# NAVSS0_TIMERMGR_0_TIMERMGR0_CFG_CONFIG register map
Vendor: Texas Instruments
Peripheral module from a debugger description file (folder J721S2).
Registers are 32-bit, read-only, reset 0x0 unless marked. A register's access mark holds for its fields unless they carry their own. Offsets are as the file gives them; lines under a group give offsets from that group; [hi:lo] are bit positions; {n}, {i} and the like mark numbered series; 'fields as' and 'values as' point back to an identical list; <NAME> marks a mode.

## NAVSS0_TIMERMGR_0_TIMERMGR0_CFG_CONFIG
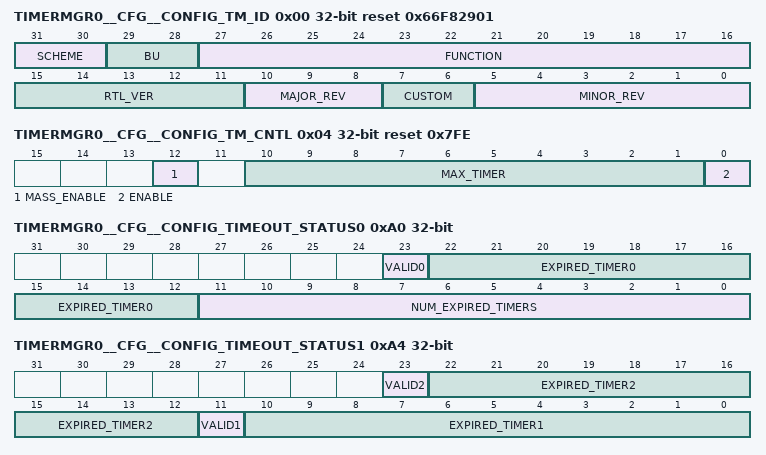
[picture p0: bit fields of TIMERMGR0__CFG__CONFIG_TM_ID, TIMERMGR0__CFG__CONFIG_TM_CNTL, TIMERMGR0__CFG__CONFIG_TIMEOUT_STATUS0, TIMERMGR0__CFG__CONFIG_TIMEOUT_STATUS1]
0x00 TIMERMGR0__CFG__CONFIG_TM_ID reset 0x66F82901 — This is the standard TI peripheral ID register that exists at address 0 in the peripheral space
  [31:30] SCHEME — PID scheme
  [29:28] BU — PID bu identifier
  [27:16] FUNCTION — PID function identifier
  [15:11] RTL_VER — PID RTL version number
  [10:8] MAJOR_REV — PID Major revision number
  [7:6] CUSTOM — PID custom
  [5:0] MINOR_REV — PID Minor revision number
0x04 TIMERMGR0__CFG__CONFIG_TM_CNTL access per field reset 0x7FE — This register controls the overall behavior of the timer manager module
  [12] MASS_ENABLE wo — Always reads zero. When a 1 is written to this bit, all timers from 0 to the TM_CNTL.max_timer will be enabled. Useful for initial programming, to not need to loop over every TIMER_CONTROL register to enable every timer if many or all are being used. This should only be used during initialization, or when TM_CNTL.enable is set to 0, as this does not set the timers, only enable them
  [10:1] MAX_TIMER rw — The maximum timer that will be checked - e.g. if only using 512 timers, set this to 511. All timers above this number will be ignored. Should be set once during initialization
  [0] ENABLE rw — Enables the timer manager. When this bit is zero, the timers will all be halted and will not count
0x08 TIMERMGR0__CFG__CONFIG_TIMER_COUNTER — This register contains the current counter value
  [31:0] COUNT — The current timer_counter value, in the timebase being used by all timers in this module
0xA0 TIMERMGR0__CFG__CONFIG_TIMEOUT_STATUS0 — This register should be read whenever the timer interrupt fires. It indicates the total number of timers that have expired and the ID of the first timer to expire. If NUM_EXPIRED_TIMERS is 1, this is the only MMR that needs to be read. Depending on the value of NUM_EXPIRED_TIMERS, either TIMEOUT_STATUS_1 or TIMEOUT_STATUS_BANK may be read by the software to avoid needing to read all 32 TIMEOUT_STATUS_N registers.
  [23] VALID0 — 1 indicates that expired_timer0 is a valid expired timer. If num_expired_timers > 0, this should always be a 1
  [22:12] EXPIRED_TIMER0 — The ID of the first timer to expire
  [11:0] NUM_EXPIRED_TIMERS — The total number of expired timers
0xA4 TIMERMGR0__CFG__CONFIG_TIMEOUT_STATUS1 — This register contains the IDs of the second and third timers to expire. It is indended as a more efficient way of finding the first few timers to expire rather than needing to read the status of all 1024 timers.
  [23] VALID2 — 1 indicates that expired_timer2 is valid
  [22:12] EXPIRED_TIMER2 — The ID of the third timer to expire
  [11] VALID1 — 1 indicates that expired_timer1 is valid
  [10:0] EXPIRED_TIMER1 — The ID of the second timer to expire
0xA8 TIMERMGR0__CFG__CONFIG_TIMEOUT_STATUS_BANK0 — This register contains the status of each timer bank for banks 31:0. When servicing the timer interrupt, if the num_expired_timers bit is greater than 3, this register may be read to see which banks contain expired timers. The TIMER_STATUS_N registers corresponding to those banks may then be read.
  [31:0] BANK_STATUS — A 1 in bit N indicates that the corresponding bank has expired timers
0x100 TIMERMGR0__CFG__CONFIG_TIMER_STATUS — Each bit is the timeout status for an individual timer. 0 = timer has not timed out or is disabled, 1 = timer has timed out
  [31:0] STATUS — Each bit is the timeout status for an individual timer
